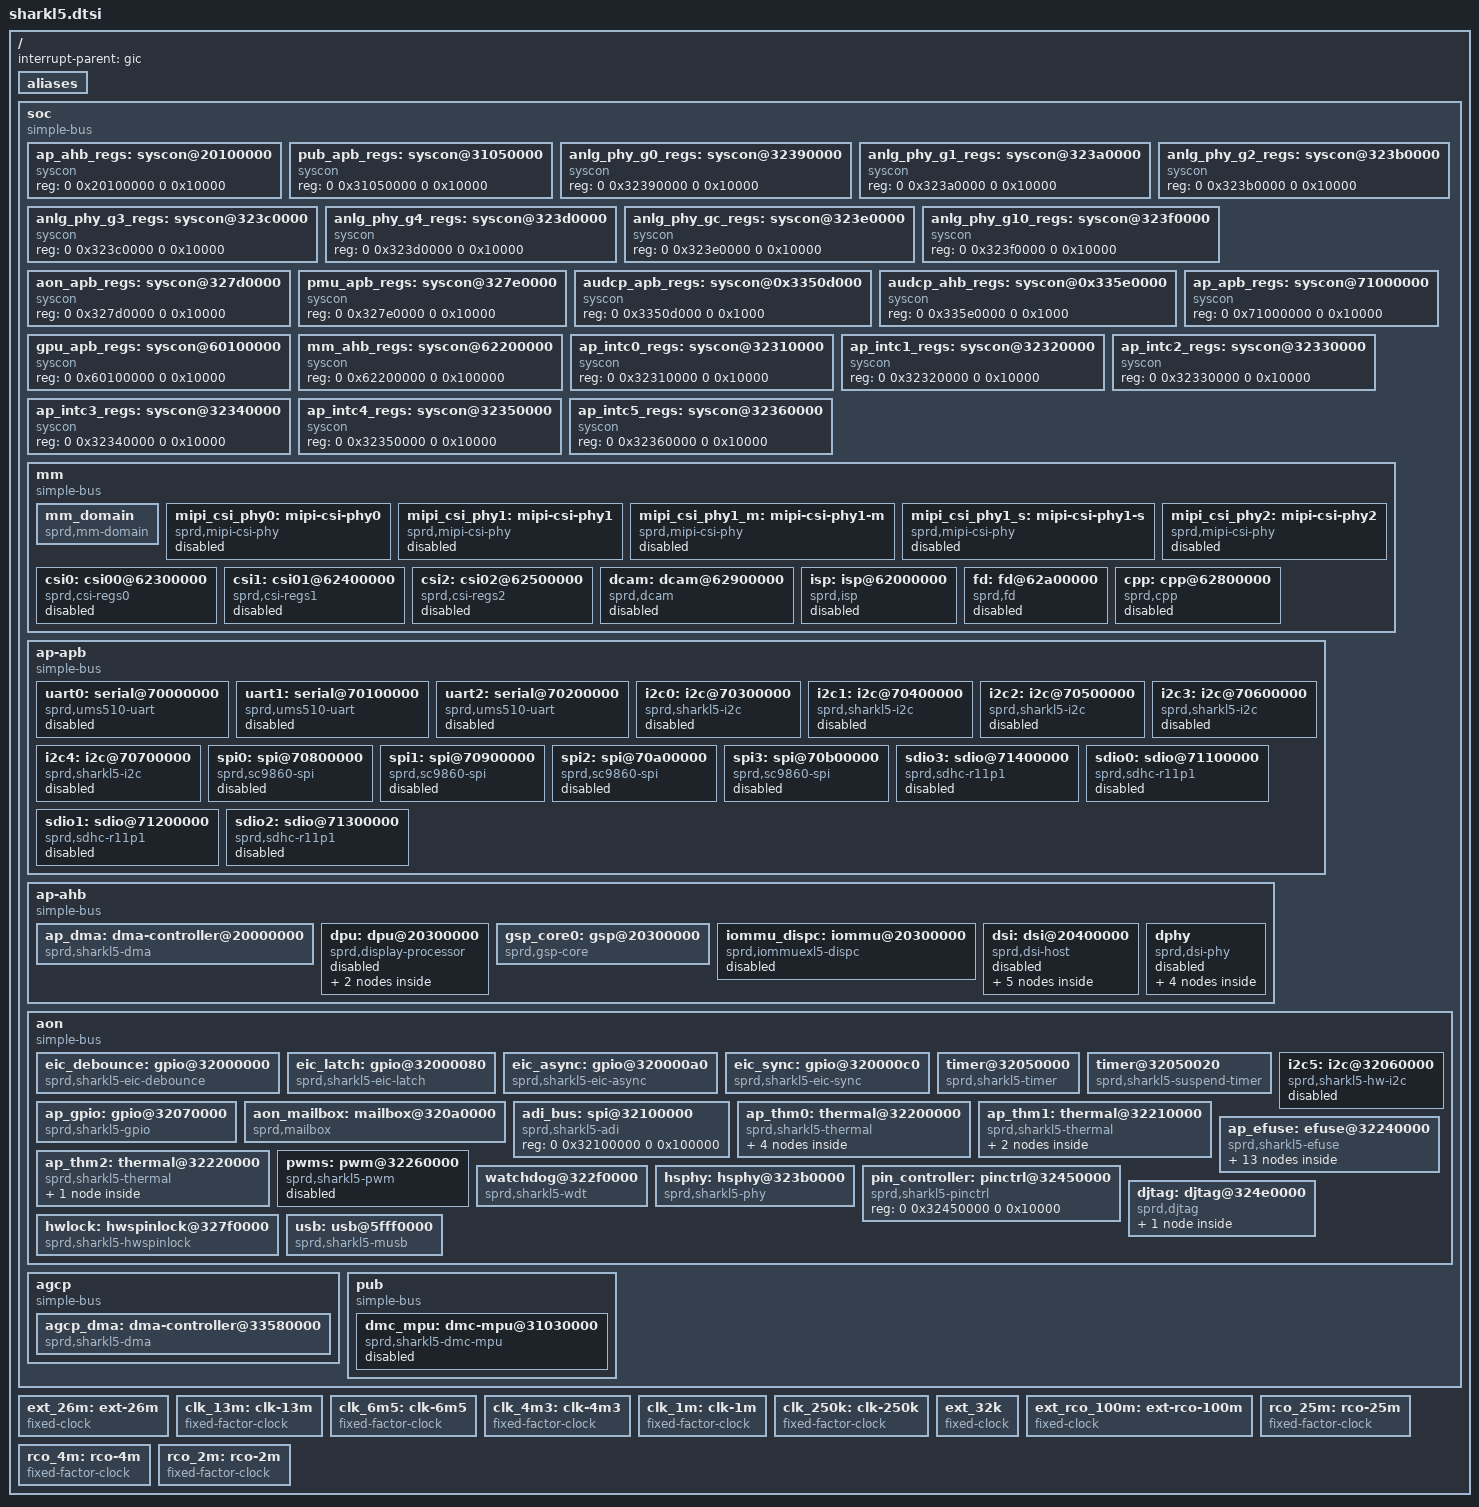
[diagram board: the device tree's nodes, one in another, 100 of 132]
// SPDX-License-Identifier: (GPL-2.0+ OR MIT)
/*
 * Spreadtrum Sharkl5 platform DTS file
 *
 * Copyright (C) 2018, Spreadtrum Communications Inc.
 */

#include <dt-bindings/soc/sprd,sharkl5-regs.h>
#include <dt-bindings/soc/sprd,sharkl5-mask.h>
#include <dt-bindings/clock/sprd,sharkl5-clk.h>
#include <dt-bindings/debug/dmc_mpu/sharkl5_dmc_mpu.h>
#include <dt-bindings/debug/busmonitor/busmonitor.h>

/ {
	interrupt-parent = <&gic>;
	#address-cells = <2>;
	#size-cells = <2>;

	aliases {
		i2c0 = &i2c0;
		i2c1 = &i2c1;
		i2c2 = &i2c2;
		i2c3 = &i2c3;
		i2c4 = &i2c4;
		i2c5 = &i2c5;
		spi0 = &spi0;
		spi1 = &spi1;
		spi2 = &spi2;
		spi3 = &spi3;
	};

	soc: soc {
		compatible = "simple-bus";
		#address-cells = <2>;
		#size-cells = <2>;
		ranges;

		ap_ahb_regs: syscon@20100000 {
			compatible = "syscon";
			#syscon-cells = <2>;
			reg = <0 0x20100000 0 0x10000>;
		};

		pub_apb_regs: syscon@31050000 {
			compatible = "syscon";
			#syscon-cells = <2>;
			reg = <0 0x31050000 0 0x10000>;
		};

		anlg_phy_g0_regs: syscon@32390000 {
			compatible = "syscon";
			#syscon-cells = <2>;
			reg = <0 0x32390000 0 0x10000>;
		};

		anlg_phy_g1_regs: syscon@323a0000 {
			compatible = "syscon";
			#syscon-cells = <2>;
			reg = <0 0x323a0000 0 0x10000>;
		};

		anlg_phy_g2_regs: syscon@323b0000 {
			compatible = "syscon";
			#syscon-cells = <2>;
			reg = <0 0x323b0000 0 0x10000>;
		};

		anlg_phy_g3_regs: syscon@323c0000 {
			compatible = "syscon";
			#syscon-cells = <2>;
			reg = <0 0x323c0000 0 0x10000>;
		};

		anlg_phy_g4_regs: syscon@323d0000 {
			compatible = "syscon";
			#syscon-cells = <2>;
			reg = <0 0x323d0000 0 0x10000>;
		};

		anlg_phy_gc_regs: syscon@323e0000 {
			compatible = "syscon";
			#syscon-cells = <2>;
			reg = <0 0x323e0000 0 0x10000>;
		};

		anlg_phy_g10_regs: syscon@323f0000 {
			compatible = "syscon";
			#syscon-cells = <2>;
			reg = <0 0x323f0000 0 0x10000>;
		};

		aon_apb_regs: syscon@327d0000 {
			compatible = "syscon";
			#syscon-cells = <2>;
			reg = <0 0x327d0000 0 0x10000>;
		};

		pmu_apb_regs: syscon@327e0000 {
			compatible = "syscon";
			#syscon-cells = <2>;
			reg = <0 0x327e0000 0 0x10000>;
		};

		audcp_apb_regs: syscon@0x3350d000 {
			compatible = "syscon";
			#syscon-cells = <2>;
			reg = <0 0x3350d000 0 0x1000>;
		};

		audcp_ahb_regs: syscon@0x335e0000 {
			compatible = "syscon";
			#syscon-cells = <2>;
			reg = <0 0x335e0000 0 0x1000>;
		};

		ap_apb_regs: syscon@71000000 {
			compatible = "syscon";
			#syscon-cells = <2>;
			reg = <0 0x71000000 0 0x10000>;
		};

		gpu_apb_regs: syscon@60100000 {
			compatible = "syscon";
			#syscon-cells = <2>;
			reg = <0 0x60100000 0 0x10000>;
		};

		mm_ahb_regs: syscon@62200000 {
			compatible = "syscon";
			#syscon-cells = <2>;
			reg = <0 0x62200000 0 0x100000>;
		};

		ap_intc0_regs: syscon@32310000 {
			compatible = "syscon";
			#syscon-cells = <2>;
			reg = <0 0x32310000 0 0x10000>;
		};

		ap_intc1_regs: syscon@32320000 {
			compatible = "syscon";
			#syscon-cells = <2>;
			reg = <0 0x32320000 0 0x10000>;
		};

		ap_intc2_regs: syscon@32330000 {
			compatible = "syscon";
			#syscon-cells = <2>;
			reg = <0 0x32330000 0 0x10000>;
		};

		ap_intc3_regs: syscon@32340000 {
			compatible = "syscon";
			#syscon-cells = <2>;
			reg = <0 0x32340000 0 0x10000>;
		};

		ap_intc4_regs: syscon@32350000 {
			compatible = "syscon";
			#syscon-cells = <2>;
			reg = <0 0x32350000 0 0x10000>;
		};

		ap_intc5_regs: syscon@32360000 {
			compatible = "syscon";
			#syscon-cells = <2>;
			reg = <0 0x32360000 0 0x10000>;
		};

		mm {
			compatible = "simple-bus";
			#address-cells = <2>;
			#size-cells = <2>;
			ranges;

			mm_domain: mm_domain {
				compatible = "sprd,mm-domain";
				syscon-names = "chip_id0",
					"chip_id1",
					"force_shutdown",
					"shutdown_en",
					"power_state",
					"mm_qos_ar",
					"mm_qos_aw";
				syscons = <&aon_apb_regs REG_AON_APB_AON_CHIP_ID0 MASK_AON_APB_AON_CHIP_ID0>,
					<&aon_apb_regs REG_AON_APB_AON_CHIP_ID1 MASK_AON_APB_AON_CHIP_ID1>,
					<&pmu_apb_regs REG_PMU_APB_PD_MM_TOP_CFG MASK_PMU_APB_PD_MM_TOP_FORCE_SHUTDOWN>,
					<&pmu_apb_regs REG_PMU_APB_PD_MM_TOP_CFG MASK_PMU_APB_PD_MM_TOP_AUTO_SHUTDOWN_EN>,
					<&pmu_apb_regs REG_PMU_APB_PWR_STATUS3_DBG MASK_PMU_APB_PD_MM_TOP_STATE>,
					<&mm_ahb_regs REG_MM_AHB_MM_QOS MASK_MM_AHB_AR_QOS_THRESHOLD_MM>,
					<&mm_ahb_regs REG_MM_AHB_MM_QOS MASK_MM_AHB_AW_QOS_THRESHOLD_MM>;

				clock-names = "mm_eb",
					"mm_ahb_eb",
					"clk_mm_ahb",
					"clk_mm_ahb_parent",
					"mm_mtx_eb",
					"clk_mm_mtx",
					"clk_mm_mtx_parent";
				clocks = <&aonapb_gate CLK_MM_EB>,
					<&mm_gate CLK_MM_CKG_EB>,
					<&mm_clk CLK_MM_AHB>,
					<&mm_clk CLK_TWPLL_153M6>,
					<&mm_gate CLK_ISP_AHB_EB>, /* TBC */
					<&mm_clk CLK_MM_MTX>,
					<&mm_clk CLK_ISPPLL_468M>;
				mm_qos = <0x0D 0x0D>; /* AR, AW */
			};
			mipi_csi_phy0: mipi-csi-phy0 {
				compatible = "sprd,mipi-csi-phy";
				syscons = <&anlg_phy_g10_regs
					REG_ANLG_PHY_G10_ANALOG_MIPI_CSI_4LANE_CSI_4L_ISO_SW
					MASK_ANLG_PHY_G10_ANALOG_MIPI_CSI_4LANE_CSI_ISO_SW_EN>,
					<&anlg_phy_g10_regs
						REG_ANLG_PHY_G10_ANALOG_MIPI_CSI_4LANE_CTRL_CSI_4L
						MASK_ANLG_PHY_G10_ANALOG_MIPI_CSI_4LANE_CSI_PS_PD_S>,
					<&anlg_phy_g10_regs
						REG_ANLG_PHY_G10_ANALOG_MIPI_CSI_4LANE_CTRL_CSI_4L
						MASK_ANLG_PHY_G10_ANALOG_MIPI_CSI_4LANE_CSI_PS_PD_L>;
				syscon-names = "iso_sw_en", "ps_pd_s", "ps_pd_l";
				sprd,phyid = <0>;
				sprd,phyname = "4lane";
				sprd,cam-ahb-syscon = <&mm_ahb_regs>;
				status = "disabled";
			};

			mipi_csi_phy1: mipi-csi-phy1 {
				compatible = "sprd,mipi-csi-phy";
				syscons = <&anlg_phy_g10_regs
						REG_ANLG_PHY_G10_ANALOG_MIPI_CSI_2P2LANE_CSI_2L_ISO_SW
						MASK_ANLG_PHY_G10_ANALOG_MIPI_CSI_2P2LANE_CSI_ISO_SW_EN>,
					<&anlg_phy_g10_regs
						REG_ANLG_PHY_G10_ANALOG_MIPI_CSI_2P2LANE_CTRL_CSI_2P2L
						MASK_ANLG_PHY_G10_ANALOG_MIPI_CSI_2P2LANE_CSI_MODE_SEL>,
					<&anlg_phy_g10_regs
						REG_ANLG_PHY_G10_ANALOG_MIPI_CSI_2P2LANE_CTRL_CSI_2P2L
						MASK_ANLG_PHY_G10_DBG_SEL_ANALOG_MIPI_CSI_2P2LANE_CSI_PS_PD_L>,
					<&anlg_phy_g10_regs
						REG_ANLG_PHY_G10_ANALOG_MIPI_CSI_2P2LANE_CTRL_CSI_2P2L
						MASK_ANLG_PHY_G10_DBG_SEL_ANALOG_MIPI_CSI_2P2LANE_CSI_PS_PD_S>;
				syscon-names = "iso_sw_en", "csi_mode_sel", "ps_pd_l", "ps_pd_s";
				sprd,phyid = <1>;
				sprd,phyname = "2p2";
				sprd,cam-ahb-syscon = <&mm_ahb_regs>;
				status = "disabled";
			};

			mipi_csi_phy1_m: mipi-csi-phy1-m {
				compatible = "sprd,mipi-csi-phy";
				syscons = <&anlg_phy_g10_regs
						REG_ANLG_PHY_G10_ANALOG_MIPI_CSI_2P2LANE_CSI_2L_ISO_SW
						MASK_ANLG_PHY_G10_ANALOG_MIPI_CSI_2P2LANE_CSI_ISO_SW_EN>,
					<&anlg_phy_g10_regs
						REG_ANLG_PHY_G10_ANALOG_MIPI_CSI_2P2LANE_CTRL_CSI_2P2L
						MASK_ANLG_PHY_G10_ANALOG_MIPI_CSI_2P2LANE_CSI_MODE_SEL>,
					<&anlg_phy_g10_regs
						REG_ANLG_PHY_G10_ANALOG_MIPI_CSI_2P2LANE_CTRL_CSI_2P2L
						MASK_ANLG_PHY_G10_DBG_SEL_ANALOG_MIPI_CSI_2P2LANE_CSI_PS_PD_L>,
					<&anlg_phy_g10_regs
						REG_ANLG_PHY_G10_ANALOG_MIPI_CSI_2P2LANE_CTRL_CSI_2P2L
						MASK_ANLG_PHY_G10_DBG_SEL_ANALOG_MIPI_CSI_2P2LANE_CSI_PS_PD_S>;
				syscon-names = "iso_sw_en", "csi_mode_sel", "ps_pd_l", "ps_pd_s";
				sprd,phyid = <3>;
				sprd,phyname = "2p2_m";
				sprd,cam-ahb-syscon = <&mm_ahb_regs>;
				status = "disabled";
			};
			mipi_csi_phy1_s: mipi-csi-phy1-s {
				compatible = "sprd,mipi-csi-phy";
				syscons = <&anlg_phy_g10_regs
						REG_ANLG_PHY_G10_ANALOG_MIPI_CSI_2P2LANE_CSI_2L_ISO_SW
						MASK_ANLG_PHY_G10_ANALOG_MIPI_CSI_2P2LANE_CSI_ISO_SW_EN>,
					<&anlg_phy_g10_regs
						REG_ANLG_PHY_G10_ANALOG_MIPI_CSI_2P2LANE_CTRL_CSI_2P2L
						MASK_ANLG_PHY_G10_ANALOG_MIPI_CSI_2P2LANE_CSI_MODE_SEL>,
					<&anlg_phy_g10_regs
						REG_ANLG_PHY_G10_ANALOG_MIPI_CSI_2P2LANE_CTRL_CSI_2P2L
						MASK_ANLG_PHY_G10_DBG_SEL_ANALOG_MIPI_CSI_2P2LANE_CSI_PS_PD_L>,
					<&anlg_phy_g10_regs
						REG_ANLG_PHY_G10_ANALOG_MIPI_CSI_2P2LANE_CTRL_CSI_2P2L
						MASK_ANLG_PHY_G10_DBG_SEL_ANALOG_MIPI_CSI_2P2LANE_CSI_PS_PD_S>;
				syscon-names = "iso_sw_en", "csi_mode_sel", "ps_pd_l", "ps_pd_s";
				sprd,phyid = <4>;
				sprd,phyname = "2p2_s";
				sprd,cam-ahb-syscon = <&mm_ahb_regs>;
				status = "disabled";
			};

			mipi_csi_phy2: mipi-csi-phy2 {
				compatible = "sprd,mipi-csi-phy";
				syscons = <&anlg_phy_g10_regs
						REG_ANLG_PHY_G10_ANALOG_MIPI_CSI_2LANE_CSI_2L_ISO_SW
						MASK_ANLG_PHY_G10_ANALOG_MIPI_CSI_2LANE_CSI_ISO_SW_EN>,
					<&anlg_phy_g10_regs
						REG_ANLG_PHY_G10_ANALOG_MIPI_CSI_2LANE_CTRL_CSI_2L
						MASK_ANLG_PHY_G10_ANALOG_MIPI_CSI_2LANE_CSI_PS_PD_S>,
					<&anlg_phy_g10_regs
						REG_ANLG_PHY_G10_ANALOG_MIPI_CSI_2LANE_CTRL_CSI_2L
						MASK_ANLG_PHY_G10_ANALOG_MIPI_CSI_2LANE_CSI_PS_PD_L>;
				syscon-names = "iso_sw_en", "ps_pd_s", "ps_pd_l";
				sprd,phyid = <2>;
				sprd,phyname = "2lane";
				sprd,cam-ahb-syscon = <&mm_ahb_regs>;
				status = "disabled";
			};

			csi0: csi00@62300000 {
				compatible = "sprd,csi-regs0";
				reg = <0 0x62300000 0 0x1000>;
				interrupts = <GIC_SPI 45 IRQ_TYPE_LEVEL_HIGH>,
					<GIC_SPI 46 IRQ_TYPE_LEVEL_HIGH>,
					<GIC_SPI 47 IRQ_TYPE_LEVEL_HIGH>,
					<GIC_SPI 48 IRQ_TYPE_LEVEL_HIGH>;
				syscons = <&mm_ahb_regs
					REG_MM_AHB_MIPI_CSI_SEL_CTRL
					(MASK_MM_AHB_MIPI_CSI_DPHY_C0_SEL0 |
					MASK_MM_AHB_MIPI_CSI_DPHY_C0_SEL1)>,
					<&mm_ahb_regs REG_MM_AHB_AHB_EB MASK_MM_AHB_CSI0_EB>,
					<&mm_ahb_regs REG_MM_AHB_AHB_RST MASK_MM_AHB_MIPI_CSI0_SOFT_RST>,
					<&mm_ahb_regs REG_MM_AHB_GEN_CLK_CFG MASK_MM_AHB_MIPI_CSI0_CKG_EN>,
					<&mm_ahb_regs REG_MM_AHB_GEN_CLK_CFG MASK_MM_AHB_CPHY_CFG_CKG_EN>;
				syscon-names = "csi_dhpy_c_sel", "csi_eb", "csi_rst", "csi_ckg_en", "cphy_ckg_en";
				sprd,csi-id = <0>;
				sprd,dcam-id = <0>;
				sprd,ip-version = <0x200>;
				status = "disable";
			};

			csi1: csi01@62400000 {
				compatible = "sprd,csi-regs1";
				reg = <0 0x62400000 0 0x1000>;
				interrupts = <GIC_SPI 49 IRQ_TYPE_LEVEL_HIGH>,
					<GIC_SPI 50 IRQ_TYPE_LEVEL_HIGH>,
					<GIC_SPI 51 IRQ_TYPE_LEVEL_HIGH>,
					<GIC_SPI 52 IRQ_TYPE_LEVEL_HIGH>;
				syscons = <&mm_ahb_regs
					REG_MM_AHB_MIPI_CSI_SEL_CTRL
					(MASK_MM_AHB_MIPI_CSI_DPHY_C1_SEL0
					| MASK_MM_AHB_MIPI_CSI_DPHY_C1_SEL1)>,
					<&mm_ahb_regs REG_MM_AHB_AHB_EB MASK_MM_AHB_CSI1_EB>,
					<&mm_ahb_regs REG_MM_AHB_AHB_RST MASK_MM_AHB_MIPI_CSI1_SOFT_RST>,
					<&mm_ahb_regs REG_MM_AHB_GEN_CLK_CFG MASK_MM_AHB_MIPI_CSI1_CKG_EN>,
					<&mm_ahb_regs REG_MM_AHB_GEN_CLK_CFG MASK_MM_AHB_CPHY_CFG_CKG_EN>;
				syscon-names = "csi_dhpy_c_sel", "csi_eb", "csi_rst", "csi_en", "cphy_ckg_en";
				sprd,csi-id = <1>;
				sprd,dcam-id = <1>;
				sprd,ip-version = <0x200>;
				status = "disable";
			};

			csi2: csi02@62500000 {
				compatible = "sprd,csi-regs2";
				reg = <0 0x62500000 0 0x1000>;
				interrupts = <GIC_SPI 53 IRQ_TYPE_LEVEL_HIGH>,
					<GIC_SPI 54 IRQ_TYPE_LEVEL_HIGH>,
					<GIC_SPI 55 IRQ_TYPE_LEVEL_HIGH>,
					<GIC_SPI 56 IRQ_TYPE_LEVEL_HIGH>;
				syscons = <&mm_ahb_regs REG_MM_AHB_MIPI_CSI_SEL_CTRL
					MASK_MM_AHB_MIPI_CSI_DPHY_C2_SEL0>,
					<&mm_ahb_regs REG_MM_AHB_AHB_EB MASK_MM_AHB_CSI2_EB>,
					<&mm_ahb_regs REG_MM_AHB_AHB_RST MASK_MM_AHB_MIPI_CSI2_SOFT_RST>,
					<&mm_ahb_regs REG_MM_AHB_GEN_CLK_CFG MASK_MM_AHB_MIPI_CSI2_CKG_EN>,
					<&mm_ahb_regs REG_MM_AHB_GEN_CLK_CFG MASK_MM_AHB_CPHY_CFG_CKG_EN>;
				syscon-names = "csi_dhpy_c_sel", "csi_eb", "csi_rst",
						"csi_en", "cphy_ckg_en";
				sprd,csi-id = <2>;
				sprd,dcam-id = <2>;
				sprd,ip-version = <0x200>;
				status = "disable";
			};
			dcam: dcam@62900000 {
				compatible = "sprd,dcam";
				reg = <0 0x62900000 0 0x1000>,
					<0 0x62901000 0 0x1000>,
					<0 0x62902000 0 0x1000>,
					<0 0x62903000 0 0x1000>;
				reg-names = "dcam0_reg",
						 "dcam1_reg",
						 "dcam2_reg",
						 "axi_ctrl_reg";
				interrupts = <GIC_SPI 57 IRQ_TYPE_LEVEL_HIGH>,
					<GIC_SPI 58 IRQ_TYPE_LEVEL_HIGH>,
					<GIC_SPI 59 IRQ_TYPE_LEVEL_HIGH>;
				interrupt-names = "dcam0",
							"dcam1",
							"dcam2";
				clock-names = "dcam_eb",
					"dcam_clk",
					"dcam_clk_192m",
					"dcam_clk_256m",
					"dcam_clk_307m2",
					"dcam_clk_384m",
					"dcam_clk_parent",
					"dcam_axi_eb",
					"dcam_axi_clk",
					"dcam_axi_clk_192m",
					"dcam_axi_clk_256m",
					"dcam_axi_clk_307m2",
					"dcam_axi_clk_384m",
					"dcam_axi_clk_parent";
				clocks = <&mm_gate CLK_MM_DCAM_EB>,
					<&mm_clk CLK_DCAM_IF>,
					<&mm_clk CLK_TWPLL_192M>,
					<&mm_clk CLK_TWPLL_256M>,
					<&mm_clk CLK_TWPLL_307M2>,
					<&mm_clk CLK_TWPLL_384M>,
					<&mm_clk CLK_TWPLL_384M>,
					<&mm_gate CLK_DCAM_AXI_EB>,
					<&mm_clk CLK_DCAM_AXI>,
					<&mm_clk CLK_TWPLL_192M>,
					<&mm_clk CLK_TWPLL_256M>,
					<&mm_clk CLK_TWPLL_307M2>,
					<&mm_clk CLK_TWPLL_384M>,
					<&mm_clk CLK_TWPLL_384M>;
				sprd,cam-ahb-syscon = <&mm_ahb_regs>;
				sprd,isp = <&isp>;
				sprd,dcam-count = <3>;
				/*iommus = <&iommu_dcam>;*/
				status = "disabled";
			};

			isp: isp@62000000 {
				compatible = "sprd,isp";
				reg = <0 0x62000000 0 0x100000>;
				interrupts = <GIC_SPI 43 IRQ_TYPE_LEVEL_HIGH>,
					<GIC_SPI 44 IRQ_TYPE_LEVEL_HIGH>;
				interrupts_name = "ispch0", "ispch1";
				clock-names = "isp_eb",
					"isp_axi_eb", /* no need read, TBC */
					"isp_clk",
					"isp_clk_256m",
					"isp_clk_307m2",
					"isp_clk_384m",
					"isp_clk_468m",
					"isp_clk_parent";
				clocks = <&mm_gate CLK_MM_ISP_EB>,
					<&mm_gate CLK_ISP_AHB_EB>,
					<&mm_clk CLK_ISP>,
					<&mm_clk CLK_TWPLL_256M>,
					<&mm_clk CLK_TWPLL_307M2>,
					<&mm_clk CLK_TWPLL_384M>,
					<&mm_clk CLK_ISPPLL_468M>,
					<&mm_clk CLK_ISPPLL_468M>;
				sprd,cam-ahb-syscon = <&mm_ahb_regs>;
				sprd,isp-count = <1>;
				/*iommus = <&iommu_isp>;*/
				status = "disabled";
			};

			fd: fd@62a00000 {
				compatible = "sprd,fd";
				reg = <0 0x62a00000 0 0x100000>;
				interrupts = <GIC_SPI 40 IRQ_TYPE_LEVEL_HIGH>;
				interrupts_name = "fdraw";
				clock-names = "fd_eb",
					"fd_axi_eb", /* no need read, TBC */
					"fd_clk",
					"fd_clk_parent";
				clocks = <&mm_gate CLK_MM_FD_EB>,
					<&mm_gate CLK_MM_ISP_EB>,
					<&mm_clk CLK_FD>,
					<&mm_clk CLK_TWPLL_384M>;
				sprd,cam-ahb-syscon = <&mm_ahb_regs>;
				/*iommus = <&iommu_fd>;*/
				status = "disabled";
			};

			cpp: cpp@62800000 {
				compatible = "sprd,cpp";
				reg = <0 0x62800000 0 0x1000>;
				interrupts = <GIC_SPI 41 IRQ_TYPE_LEVEL_HIGH>;
				clock-names = "cpp_eb",
					"cpp_axi_eb", /* no need read, TBC */
					"cpp_clk",
					"cpp_clk_parent";
				clocks = <&mm_gate CLK_MM_CPP_EB>,
					<&mm_gate CLK_MM_ISP_EB>,
					<&mm_clk CLK_CPP>,
					<&mm_clk CLK_TWPLL_307M2>;
				sprd,cam-ahb-syscon = <&mm_ahb_regs>;
				/*iommus = <&iommu_cpp>;*/
				status = "disabled";
			};

		};

		ap-apb {
			compatible = "simple-bus";
			#address-cells = <2>;
			#size-cells = <2>;
			ranges;

			uart0: serial@70000000 {
				compatible = "sprd,ums510-uart",
					     "sprd,sc9836-uart";
				reg = <0 0x70000000 0 0x100>;
				interrupts = <GIC_SPI 2 IRQ_TYPE_LEVEL_HIGH>;
				status = "disabled";
			};

			uart1: serial@70100000 {
				compatible = "sprd,ums510-uart",
					     "sprd,sc9836-uart";
				reg = <0 0x70100000 0 0x100>;
				interrupts = <GIC_SPI 3 IRQ_TYPE_LEVEL_HIGH>;
				status = "disabled";
			};

			uart2: serial@70200000 {
				compatible = "sprd,ums510-uart",
					     "sprd,sc9836-uart";
				reg = <0 0x70200000 0 0x100>;
				interrupts = <GIC_SPI 4 IRQ_TYPE_LEVEL_HIGH>;
				status = "disabled";
			};

			i2c0: i2c@70300000 {
				compatible = "sprd,sharkl5-i2c";
				reg = <0 0x70300000 0 0x100>;
				interrupts = <GIC_SPI 11 IRQ_TYPE_LEVEL_HIGH>;
				clock-frequency = <400000>;
				#address-cells = <1>;
				#size-cells = <0>;
				status = "disabled";
			};

			i2c1: i2c@70400000 {
				compatible = "sprd,sharkl5-i2c";
				reg = <0 0x70400000 0 0x100>;
				interrupts = <GIC_SPI 12 IRQ_TYPE_LEVEL_HIGH>;
				clock-frequency = <400000>;
				#address-cells = <1>;
				#size-cells = <0>;
				status = "disabled";
			};

			i2c2: i2c@70500000 {
				compatible = "sprd,sharkl5-i2c";
				reg = <0 0x70500000 0 0x100>;
				interrupts = <GIC_SPI 13 IRQ_TYPE_LEVEL_HIGH>;
				clock-frequency = <400000>;
				#address-cells = <1>;
				#size-cells = <0>;
				status = "disabled";
			};

			i2c3: i2c@70600000 {
				compatible = "sprd,sharkl5-i2c";
				reg = <0 0x70600000 0 0x100>;
				interrupts = <GIC_SPI 14 IRQ_TYPE_LEVEL_HIGH>;
				clock-frequency = <400000>;
				#address-cells = <1>;
				#size-cells = <0>;
				status = "disabled";
			};

			i2c4: i2c@70700000 {
				compatible = "sprd,sharkl5-i2c";
				reg = <0 0x70700000 0 0x100>;
				interrupts = <GIC_SPI 15 IRQ_TYPE_LEVEL_HIGH>;
				clock-frequency = <400000>;
				#address-cells = <1>;
				#size-cells = <0>;
				status = "disabled";
			};

			spi0: spi@70800000{
				compatible = "sprd,sc9860-spi",
					     "sprd,sharkl5-spi";
				reg = <0 0x70800000 0 0x1000>;
				interrupts = <GIC_SPI 5 IRQ_TYPE_LEVEL_HIGH>;
				#address-cells = <1>;
				#size-cells = <0>;
				status = "disabled";
			};

			spi1: spi@70900000{
				compatible = "sprd,sc9860-spi",
					     "sprd,sharkl5-spi";
				reg = <0 0x70900000 0 0x1000>;
				interrupts = <GIC_SPI 6 IRQ_TYPE_LEVEL_HIGH>;
				#address-cells = <1>;
				#size-cells = <0>;
				status = "disabled";
			};

			spi2: spi@70a00000{
				compatible = "sprd,sc9860-spi",
					     "sprd,sharkl5-spi";
				reg = <0 0x70a00000 0 0x1000>;
				interrupts = <GIC_SPI 7 IRQ_TYPE_LEVEL_HIGH>;
				#address-cells = <1>;
				#size-cells = <0>;
				status = "disabled";
			};

			spi3: spi@70b00000{
				compatible = "sprd,sc9860-spi",
					     "sprd,sharkl5-spi";
				reg = <0 0x70b00000 0 0x1000>;
				interrupts = <GIC_SPI 8 IRQ_TYPE_LEVEL_HIGH>;
				#address-cells = <1>;
				#size-cells = <0>;
				status = "disabled";
			};

			sdio3: sdio@71400000 {
				compatible = "sprd,sdhc-r11p1";
				reg = <0 0x71400000 0 0x1000>;
				interrupts = <GIC_SPI 10 IRQ_TYPE_LEVEL_HIGH>;
				status = "disabled";
			};

			sdio0: sdio@71100000 {
				compatible = "sprd,sdhc-r11p1";
				reg = <0 0x71100000 0 0x1000>;
				interrupts = <GIC_SPI 19 IRQ_TYPE_LEVEL_HIGH>;
				status = "disabled";
			};

			sdio1: sdio@71200000 {
				compatible = "sprd,sdhc-r11p1";
				reg = <0 0x71200000 0 0x1000>;
				interrupts = <GIC_SPI 20 IRQ_TYPE_LEVEL_HIGH>;
				status = "disabled";
			};

			sdio2: sdio@71300000 {
				compatible = "sprd,sdhc-r11p1";
				reg = <0 0x71300000 0 0x1000>;
				interrupts = <GIC_SPI 21 IRQ_TYPE_LEVEL_HIGH>;
				status = "disabled";
			};
		};

		ap-ahb {
			compatible = "simple-bus";
			#address-cells = <2>;
			#size-cells = <2>;
			ranges;

			ap_dma: dma-controller@20000000 {
				compatible = "sprd,sharkl5-dma";
				reg = <0 0x20000000 0 0x4000>;
				interrupts = <GIC_SPI 24 IRQ_TYPE_LEVEL_HIGH>;
				#dma-cells = <1>;
				#dma-channels = <32>;
				clock-names = "enable";
				clocks = <&apahb_gate CLK_DMA_EB>;
			};

			dpu: dpu@20300000 {
				compatible = "sprd,display-processor";
				reg = <0x0 0x20300000 0x0 0x1000>;
				syscons = <&ap_ahb_regs REG_AP_AHB_AHB_RST
					MASK_AP_AHB_DISPC_SOFT_RST>;
				syscon-names = "reset";
				interrupts = <GIC_SPI 27 IRQ_TYPE_LEVEL_HIGH>;
				status = "disabled";

				dma-coherent;

				sprd,ip = "dpu-lite-r2p0";
				sprd,soc = "sharkl5";

				dpu_port: port {
					dpu_out: endpoint {
						remote-endpoint = <&dsi_in>;
					};
				};
			};

			gsp_core0: gsp@20300000 {
				compatible = "sprd,gsp-core";
				reg = <0 0x20300000  0 0x2000>;
				core-id = <0>;
				kcfg-num = <16>;
				interrupts = <GIC_SPI 26 IRQ_TYPE_LEVEL_HIGH>;
				iommus = <&iommu_dispc>;
			};

			iommu_dispc: iommu@20300000 {
				compatible = "sprd,iommuexl5-dispc";
				reg = <0x0 0x20300000 0x0 0x800>,
				      <0x0 0x20300800 0x0 0x80>;
				iova-base = <0x0 0x30000000>;
				iova-size = <0x0 0x10000000>;
				reg_name = "mmu_interrupt_reg","mmu_reg";
				status = "disabled";
				#iommu-cells = <0>;
			};

			dsi: dsi@20400000 {
				compatible = "sprd,dsi-host";
				reg = <0x0 0x20400000 0x0 0x1000>;
				syscons = <&ap_ahb_regs REG_AP_AHB_AHB_RST
					MASK_AP_AHB_DSI_SOFT_RST>;
				syscon-names = "reset";
				interrupts = <GIC_SPI 30 IRQ_TYPE_LEVEL_HIGH>,
					<GIC_SPI 31 IRQ_TYPE_LEVEL_HIGH>;
				status = "disabled";

				sprd,ip = "sprd,dsi-ctrl", "r3p1";
				sprd,soc = "sharkl5";

				ports {
					#address-cells = <1>;
					#size-cells = <0>;

					port@0 {
						reg = <0>;
						dsi_out: endpoint {
							remote-endpoint = <&dphy_in>;
						};
					};

					port@1 {
						reg = <1>;
						dsi_in: endpoint {
							remote-endpoint = <&dpu_out>;
						};
					};
				};
			};

			dphy: dphy {
				compatible = "sprd,dsi-phy";
				#address-cells = <1>;
				#size-cells = <0>;
				reg = <0x0 0x20400000 0x0 0x1000>;
				syscons = <&ap_ahb_regs
					REG_AP_AHB_MISC_CKG_EN
					(MASK_AP_AHB_DPHY_REF_CKG_EN |
					MASK_AP_AHB_DPHY_CFG_CKG_EN)>,
					<&pmu_apb_regs
					REG_PMU_APB_ANALOG_PHY_PD_CFG
					MASK_PMU_APB_DSI_PD_REG>;
				syscon-names = "enable", "power";
				status = "disabled";

				sprd,ip = "sprd,megacores-sharkl5";
				sprd,soc = "sharkl5";

				/* output port */
				port@0 {
					reg = <0>;
					dphy_out: endpoint {
						remote-endpoint = <&panel_in>;
					};
				};

				/* input port*/
				port@1 {
					reg = <1>;
					dphy_in: endpoint {
						remote-endpoint = <&dsi_out>;
					};
				};
			};

		};

		aon {
			compatible = "simple-bus";
			#address-cells = <2>;
			#size-cells = <2>;
			ranges;

			eic_debounce: gpio@32000000 {
				compatible = "sprd,sharkl5-eic-debounce";
				reg = <0 0x32020000 0 0x80>,
				      <0 0x32030000 0 0x80>;
				gpio-controller;
				#gpio-cells = <2>;
				interrupt-controller;
				#interrupt-cells = <2>;
				interrupts = <GIC_SPI 72 IRQ_TYPE_LEVEL_HIGH>;
			};

			eic_latch: gpio@32000080 {
				compatible = "sprd,sharkl5-eic-latch";
				reg = <0 0x32020080 0 0x20>,
				      <0 0x32030080 0 0x20>;
				gpio-controller;
				#gpio-cells = <2>;
				interrupt-controller;
				#interrupt-cells = <2>;
				interrupts = <GIC_SPI 72 IRQ_TYPE_LEVEL_HIGH>;
			};

			eic_async: gpio@320000a0 {
				compatible = "sprd,sharkl5-eic-async";
				reg = <0 0x320200a0 0 0x20>,
				      <0 0x320300a0 0 0x20>;
				gpio-controller;
				#gpio-cells = <2>;
				interrupt-controller;
				#interrupt-cells = <2>;
				interrupts = <GIC_SPI 72 IRQ_TYPE_LEVEL_HIGH>;
			};

			eic_sync: gpio@320000c0 {
				compatible = "sprd,sharkl5-eic-sync";
				reg = <0 0x320200c0 0 0x20>,
				      <0 0x320300c0 0 0x20>;
				gpio-controller;
				#gpio-cells = <2>;
				interrupt-controller;
				#interrupt-cells = <2>;
				interrupts = <GIC_SPI 72 IRQ_TYPE_LEVEL_HIGH>;
			};

			timer@32050000 {
				compatible = "sprd,sharkl5-timer";
				reg = <0 0x32050000 0 0x20>;
				interrupts = <GIC_SPI 71 IRQ_TYPE_LEVEL_HIGH>;
				clocks = <&ext_32k>;
			};

			timer@32050020 {
				compatible = "sprd,sharkl5-suspend-timer";
				reg = <0 0x32050020 0 0x20>;
				clocks = <&ext_32k>;
			};

			i2c5: i2c@32060000 {
				compatible = "sprd,sharkl5-hw-i2c";
				reg = <0 0x32060000 0 0x1000>;
				interrupts = <GIC_SPI 68 IRQ_TYPE_LEVEL_HIGH>;
				clock-names = "source", "enable", "i2c",
						"clk_hw_i2c";
				clock-frequency = <400000>;
				#address-cells = <1>;
				#size-cells = <0>;
				status = "disabled";
			};

			ap_gpio: gpio@32070000 {
				compatible = "sprd,sharkl5-gpio";
				reg = <0 0x32070000 0 0x10000>;
				gpio-controller;
				#gpio-cells = <2>;
				interrupt-controller;
				#interrupt-cells = <2>;
				interrupts = <GIC_SPI 61 IRQ_TYPE_LEVEL_HIGH>;
			};

			aon_mailbox: mailbox@320a0000 {
				compatible = "sprd,mailbox";
				reg = <0 0x320a0000 0 0x8000>,
				      <0 0x320a8000 0 0x8000>;
				syscons = <&aon_apb_regs 0x4 0x4>;
				syscon-names = "clk";
				interrupts = <GIC_SPI 82 IRQ_TYPE_LEVEL_HIGH>,
					     <GIC_SPI 83 IRQ_TYPE_LEVEL_HIGH>,
					     <GIC_SPI 84 IRQ_TYPE_LEVEL_HIGH>;
				sprd,sensor = <6>;
				sprd,core-cnt = <7>;
				sprd,version = <3>;
			};

			adi_bus: spi@32100000 {
				compatible = "sprd,sharkl5-adi";
				reg = <0 0x32100000 0 0x100000>;
				#address-cells = <1>;
				#size-cells = <0>;
			};

			ap_thm0: thermal@32200000 {
				compatible = "sprd,sharkl5-thermal";
				reg = <0 0x32200000 0 0x10000>;
				clock-names = "enable";
				clocks = <&aonapb_gate CLK_THM0_EB>;
				#thermal-sensor-cells = <1>;
				nvmem-cells = <&thm0_sign>, <&thm0_ratio>;
				nvmem-cell-names = "thm_sign_cal", "thm_ratio_cal";

				prometheus0-sensor@0{
					reg = <0>;
					nvmem-cells = <&thm0_sen0>;
					nvmem-cell-names = "sen_delta_cal";
				};

				ank1-sensor@1{
					reg = <1>;
					nvmem-cells = <&thm0_sen1>;
					nvmem-cell-names = "sen_delta_cal";
				};

				ank2-sensor@2{
					reg = <2>;
					nvmem-cells = <&thm0_sen2>;
					nvmem-cell-names = "sen_delta_cal";
				};

				prometheus1-sensor@3{
					reg = <3>;
					nvmem-cells = <&thm0_sen3>;
					nvmem-cell-names = "sen_delta_cal";
				};
			};

			ap_thm1: thermal@32210000 {
				compatible = "sprd,sharkl5-thermal";
				reg = <0 0x32210000 0 0x10000>;
				clock-names = "enable";
				clocks = <&aonapb_gate CLK_THM1_EB>;
				#thermal-sensor-cells = <1>;
				nvmem-cells = <&thm1_sign>, <&thm1_ratio>;
				nvmem-cell-names = "thm_sign_cal", "thm_ratio_cal";

				cputop-sensor@0{
					reg = <0>;
					nvmem-cells = <&thm1_sen0>;
					nvmem-cell-names = "sen_delta_cal";
				};

				ank0-sensor@1{
					reg = <1>;
					nvmem-cells = <&thm1_sen1>;
					nvmem-cell-names = "sen_delta_cal";
				};
			};

			ap_thm2: thermal@32220000 {
				compatible = "sprd,sharkl5-thermal";
				reg = <0 0x32220000 0 0x10000>;
				clock-names = "enable";
				clocks = <&aonapb_gate CLK_THM2_EB>;
				#thermal-sensor-cells = <1>;
				nvmem-cells = <&thm2_sign>, <&thm2_ratio>;
				nvmem-cell-names = "thm_sign_cal", "thm_ratio_cal";

				gpu-sensor@0{
					reg = <0>;
					nvmem-cells = <&thm2_sen0>;
					nvmem-cell-names = "sen_delta_cal";
				};
			};

			ap_efuse: efuse@32240000 {
				compatible = "sprd,sharkl5-efuse";
				reg = <0 0x32240000 0 0x10000>;
				clock-names = "enable";
				hwlocks = <&hwlock 8>;
				clocks = <&aonapb_gate CLK_EFUSE_EB>;

				thm0_sign: thm0-sign@56{
					reg = <0x56 0x4>;
					bits = <0 1>;
				};

				thm0_ratio: thm0-ratio@56{
					reg = <0x56 0x4>;
					bits = <1 7>;
				};

				thm0_sen0: thm0-sen0@56{
					reg = <0x56 0x4>;
					bits = <8 8>;
				};

				thm0_sen1: thm0-sen1@58{
					reg = <0x58 0x4>;
					bits = <8 8>;
				};

				thm0_sen2: thm0-sen2@58{
					reg = <0x58 0x4>;
					bits = <0 8>;
				};

				thm0_sen3: thm0-sen3@58{
					reg = <0x58 0x4>;
					bits = <24 8>;
				};

				thm1_sign: thm1-sign@57{
					reg = <0x57 0x4>;
					bits = <0 1>;
				};

				thm1_ratio: thm1-ratio@57{
					reg = <0x57 0x4>;
					bits = <1 7>;
				};

				thm1_sen0: thm1-sen0@57{
					reg = <0x57 0x4>;
					bits = <8 8>;
				};

				thm1_sen1: thm1-sen1@58{
					reg = <0x58 0x4>;
					bits = <16 8>;
				};

				thm2_sign: thm2-sign@57{
					reg = <0x57 0x4>;
					bits = <16 1>;
				};

				thm2_ratio: thm2-ratio@57{
					reg = <0x57 0x4>;
					bits = <17 7>;
				};

				thm2_sen0: thm2-sen0@57{
					reg = <0x57 0x4>;
					bits = <24 8>;
				};
			};

			pwms: pwm@32260000 {
				compatible = "sprd,sharkl5-pwm";
				reg = <0 0x32260000 0 0x10000>;
				status = "disabled";
				clock-names = "clk_parent",
					"clk_pwm0", "clk_pwm0_eb",
					"clk_pwm1", "clk_pwm1_eb",
					"clk_pwm2", "clk_pwm2_eb",
					"clk_pwm3", "clk_pwm3_eb";
				clocks = <&ext_26m>,
					<&aon_clk CLK_PWM0>,
					<&aonapb_gate CLK_PWM0_EB>,
					<&aon_clk CLK_PWM1>,
					<&aonapb_gate CLK_PWM1_EB>,
					<&aon_clk CLK_PWM2>,
					<&aonapb_gate CLK_PWM2_EB>,
					<&aon_clk CLK_PWM3>,
					<&aonapb_gate CLK_PWM3_EB>;
				#pwm-cells = <2>;
			};

			watchdog@322f0000 {
				compatible = "sprd,sharkl5-wdt";
				reg = <0 0x322f0000 0 0x10000>;
				interrupts = <GIC_SPI 79 IRQ_TYPE_LEVEL_HIGH>;
				timeout-sec = <12>;
				clock-names = "enable", "rtc_enable";
				clocks = <&aonapb_gate CLK_APCPU_WDG_EB>,
					<&aonapb_gate CLK_AP_WDG_RTC_EB>;
			};

			hsphy: hsphy@323b0000 {
				compatible = "sprd,sharkl5-phy";
				sprd,syscon-enable = <&aon_apb_regs>;
				sprd,syscon-anag2 = <&anlg_phy_g2_regs>;
				sprd,vdd-voltage = <3300000>;
				#phy-cells = <0>;
			};

			pin_controller: pinctrl@32450000 {
				compatible = "sprd,sharkl5-pinctrl";
				reg = <0 0x32450000 0 0x10000>;
			};

			djtag: djtag@324e0000 {
				compatible = "sprd,djtag";
				reg = <0 0x324e0000 0 0x1000>;
				syscon-names = "soft_rst";
				syscons = <&aon_apb_regs REG_AON_APB_APB_RST3
					MASK_AON_APB_DJTAG_SOFT_RST>;
				clock-names = "enable", "tck";
				clocks = <&aonapb_gate CLK_DJTAG_EB>,
					<&aonapb_gate CLK_DJTAG_TCK_EB>;
				hwlocks = <&hwlock 10>;
				hwlock-names = "djtag";

				#address-cells = <1>;
				#size-cells = <0>;

				aon-busmonitor@8{
					compatible  = "sprd,sharkl3-busmonitor";
					interrupts = <GIC_SPI 81
						IRQ_TYPE_LEVEL_HIGH>;
					reg = <0x8>;
					sprd,bm-num = <6>;
					sprd,bm-name =
						"AP", "WTLCP", "AUDCP", "PUBCP",
						"USBOTG", "CM4";
					sprd,bm-type =
						<AXI>, <AXI>, <AXI>, <AXI>,
						<AXI>, <AXI>, <AXI>;
					sprd,bm-dap = <0>, <1>, <2>, <3>,
						<4>, <5>;
					sprd,bm-config =
						<DISABLE MON_WRITE MON_INSIDE>,
						<DISABLE MON_WRITE MON_INSIDE>,
						<DISABLE MON_WRITE MON_INSIDE>,
						<DISABLE MON_WRITE MON_INSIDE>,
						<DISABLE MON_WRITE MON_INSIDE>,
						<DISABLE MON_WRITE MON_INSIDE>;
					sprd,bm-id =
						<DISABLE 0 AXIID>,
						<DISABLE 0 AXIID>,
						<DISABLE 0 AXIID>,
						<DISABLE 0 AXIID>,
						<DISABLE 0 AXIID>,
						<DISABLE 0 AXIID>;
					sprd,bm-ranges =
						<0 0>, <0 0>, <0 0>,
						<0 0>, <0 0>, <0 0>;
				};
			};

			hwlock: hwspinlock@327f0000 {
				compatible = "sprd,sharkl5-hwspinlock";
				reg = <0 0x327f0000 0 0x10000>;
				#hwlock-cells = <1>;
				clock-names = "enable";
				clocks = <&aonapb_gate CLK_SPLK_EB>;
			};

			usb: usb@5fff0000 {
				compatible = "sprd,sharkl5-musb";
				reg = <0 0x5fff0000 0 0x2000>;
				interrupts = <GIC_SPI 69 IRQ_TYPE_LEVEL_HIGH>;
				interrupt-names = "mc";
				clocks = <&aonapb_gate CLK_OTG_UTMI_EB>;
				clock-names = "core_clk";
				usb-phy = <&hsphy>;
				phy-names = "usb";
				dr-mode = "peripheral";
			};
		};

		agcp {
			compatible = "simple-bus";
			#address-cells = <2>;
			#size-cells = <2>;
			ranges;

			agcp_dma: dma-controller@33580000 {
				compatible = "sprd,sharkl5-dma";
				reg = <0 0x33580000 0 0x4000>;
				#dma-cells = <1>;
				#dma-channels = <32>;
				clock-names = "enable", "ashb_eb";
				clocks = <&audcpahb_gate CLK_AUDCP_DMA_AP_EB>,
					 <&audcpahb_gate CLK_AUDCP_DMA_AP_ASHB_EB>;
			};
		};

		pub {
			compatible = "simple-bus";
			#address-cells = <2>;
			#size-cells = <2>;
			ranges;

			dmc_mpu: dmc-mpu@31030000 {
				compatible = "sprd,sharkl5-dmc-mpu";
				reg = <0 31030000 0 0x10000>;
				interrupts = <GIC_SPI 61 IRQ_TYPE_LEVEL_HIGH>;
				syscon-names = "irq_clr", "irq_en";
				syscons = <&pub_apb_regs
					REG_PUB_APB_PUB_INT_CTRL
					MASK_PUB_APB_DMC_MPU_VIO_INT_CLR>,
					<&pub_apb_regs
					REG_PUB_APB_PUB_INT_CTRL
					MASK_PUB_APB_DMC_MPU_VIO_INT_EN>;
				sprd,channel-num = <8>;
				sprd,mpu-num = <16>;
				sprd,channel-names =
					"CPU", "GPU", "DPU/DCAM","ISP",
					"AP/VSP/AON", "WTLCP", "PUBCP/AUDCP",
					"SHARED0", "SHARED1", "SHARED2",
					"SHARED3", "SHARED4", "SHARED5",
					"SHARED6", "SHARED7", "SHARED8";
				sprd,ranges = <0 0 0 0>, <0 0 0 0>, <0 0 0 0>,
					<0 0 0 0>, <0 0 0 0>, <0 0 0 0>,
					<0 0 0 0>, <0 0 0 0>, <0 0 0 0>,
					<0 0 0 0>, <0 0 0 0>, <0 0 0 0>,
					<0 0 0 0>, <0 0 0 0>, <0 0 0 0>,
					<0 0 0 0>;
				sprd,chn-config =
					<DISABLE MON_INSIDE MON_WRITE>,
					<DISABLE MON_INSIDE MON_WRITE>,
					<DISABLE MON_INSIDE MON_WRITE>,
					<DISABLE MON_INSIDE MON_WRITE>,
					<DISABLE MON_INSIDE MON_WRITE>,
					<DISABLE MON_INSIDE MON_WRITE>,
					<DISABLE MON_INSIDE MON_WRITE>,
					<DISABLE MON_INSIDE MON_WRITE>,
					<DISABLE MON_INSIDE MON_WRITE>,
					<DISABLE MON_INSIDE MON_WRITE>,
					<DISABLE MON_INSIDE MON_WRITE>,
					<DISABLE MON_INSIDE MON_WRITE>,
					<DISABLE MON_INSIDE MON_WRITE>,
					<DISABLE MON_INSIDE MON_WRITE>,
					<DISABLE MON_INSIDE MON_WRITE>,
					<DISABLE MON_INSIDE MON_WRITE>;
				sprd,id-config =
					<MPUID 0 0xffff>, <MPUID 0 0xffff>,
					<MPUID 0 0xffff>, <MPUID 0 0xffff>,
					<MPUID 0 0xffff>, <MPUID 0 0xffff>,
					<MPUID 0 0xffff>, <MPUID 0 0xffff>,
					<MPUID 0 0xffff>, <MPUID 0 0xffff>,
					<MPUID 0 0xffff>, <MPUID 0 0xffff>,
					<MPUID 0 0xffff>, <MPUID 0 0xffff>,
					<MPUID 0 0xffff>, <MPUID 0 0xffff>;
				sprd,port-map = <0>, <1>, <2>, <3>, <4>,
						<5>, <6>, <0>, <0>, <0>,
						<0>, <0>, <0>, <0>, <0>,
						<0>;
				sprd,ddr-offset = <0x80000000>;
				status = "disabled";
			};
		};
	};

	ext_26m: ext-26m {
		compatible = "fixed-clock";
		#clock-cells = <0>;
		clock-frequency = <26000000>;
		clock-output-names = "ext-26m";
	};

	clk_13m: clk-13m {
		compatible = "fixed-factor-clock";
		#clock-cells = <0>;
		clock-mult = <1>;
		clock-div = <2>;
		clocks = <&ext_26m>;
		clock-output-names = "clk-13m";
	};

	clk_6m5: clk-6m5 {
		compatible = "fixed-factor-clock";
		#clock-cells = <0>;
		clock-mult = <1>;
		clock-div = <4>;
		clocks = <&ext_26m>;
		clock-output-names = "clk-6m5";
	};

	clk_4m3: clk-4m3 {
		compatible = "fixed-factor-clock";
		#clock-cells = <0>;
		clock-mult = <1>;
		clock-div = <6>;
		clocks = <&ext_26m>;
		clock-output-names = "clk-4m3";
	};

	clk_1m: clk-1m {
		compatible = "fixed-factor-clock";
		#clock-cells = <0>;
		clock-mult = <1>;
		clock-div = <26>;
		clocks = <&ext_26m>;
		clock-output-names = "clk-1m";
	};

	clk_250k: clk-250k {
		compatible = "fixed-factor-clock";
		#clock-cells = <0>;
		clock-mult = <1>;
		clock-div = <104>;
		clocks = <&ext_26m>;
		clock-output-names = "clk-250k";
	};

	ext_32k: ext_32k {
		compatible = "fixed-clock";
		#clock-cells = <0>;
		clock-frequency = <32768>;
		clock-output-names = "ext-32k";
	};

	ext_rco_100m: ext-rco-100m {
		compatible = "fixed-clock";
		#clock-cells = <0>;
		clock-frequency = <100000000>;
		clock-output-names = "ext-rco-100m";
	};

	rco_25m: rco-25m {
		compatible = "fixed-factor-clock";
		#clock-cells = <0>;
		clock-mult = <1>;
		clock-div = <4>;
		clocks = <&ext_rco_100m>;
		clock-output-names = "rco-25m";
	};

	rco_4m: rco-4m {
		compatible = "fixed-factor-clock";
		#clock-cells = <0>;
		clock-mult = <1>;
		clock-div = <25>;
		clocks = <&ext_rco_100m>;
		clock-output-names = "rco-4m";
	};

	rco_2m: rco-2m {
		compatible = "fixed-factor-clock";
		#clock-cells = <0>;
		clock-mult = <1>;
		clock-div = <50>;
		clocks = <&ext_rco_100m>;
		clock-output-names = "rco-2m";
	};
};
